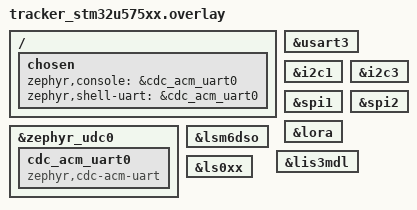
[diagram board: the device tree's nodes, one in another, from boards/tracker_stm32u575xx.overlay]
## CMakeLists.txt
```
cmake_minimum_required(VERSION 3.20.0)

list(APPEND ZEPHYR_EXTRA_MODULES
  ${CMAKE_CURRENT_SOURCE_DIR}/../../lib/ahrs
)

find_package(Zephyr REQUIRED HINTS $ENV{ZEPHYR_BASE})
project(compass_sample)

target_sources(app PRIVATE src/main.c)
```

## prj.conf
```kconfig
# Console over RTT (STLink v2 / OpenOCD)
CONFIG_LOG=y
CONFIG_LOG_BACKEND_RTT=y
CONFIG_LOG_BACKEND_UART=n
CONFIG_USE_SEGGER_RTT=y
CONFIG_CONSOLE=y
CONFIG_RTT_CONSOLE=y
CONFIG_UART_CONSOLE=n

# Sensors
CONFIG_SENSOR=y
CONFIG_I2C=y
CONFIG_LSM6DSO=y
CONFIG_LSM6DSO_TRIGGER_NONE=y
CONFIG_LIS3MDL=y
CONFIG_LIS3MDL_TRIGGER_NONE=y
CONFIG_LIS3MDL_ODR="20"

# AHRS library
CONFIG_AHRS=y
CONFIG_AHRS_ALPHA_X1000=960
CONFIG_AHRS_DT_MS=50

# Float printing
CONFIG_CBPRINTF_FP_SUPPORT=y

# FPU (Cortex-M33)
CONFIG_FPU=y

# Power domains (3V3 rail for sensors)
CONFIG_PM_DEVICE=y
CONFIG_PM_DEVICE_RUNTIME=y
CONFIG_PM_DEVICE_POWER_DOMAIN=y
CONFIG_TIMEOUT_64BIT=y
CONFIG_POWER_DOMAIN=y
CONFIG_POWER_DOMAIN_GPIO_INIT_PRIORITY=1

# Stack
CONFIG_MAIN_STACK_SIZE=4096
```

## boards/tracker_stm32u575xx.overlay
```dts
/*
 * Route console/log output to USB CDC ACM on the Tracker board.
 *
 * Power domains are removed from peripheral nodes to avoid init-ordering
 * conflicts. main.c drives the power GPIOs directly.
 */

&zephyr_udc0 {
	cdc_acm_uart0: cdc_acm_uart0 {
		compatible = "zephyr,cdc-acm-uart";
	};
};

/ {
	chosen {
		zephyr,console = &cdc_acm_uart0;
		zephyr,shell-uart = &cdc_acm_uart0;
	};
};

&usart3 { /delete-property/ power-domains; };
&i2c1   { /delete-property/ power-domains; };
&i2c3   { /delete-property/ power-domains; };
&spi1   { /delete-property/ power-domains; };
&spi2   { /delete-property/ power-domains; };
&lora   { /delete-property/ power-domains; };
&lsm6dso { /delete-property/ power-domains; };
&lis3mdl { /delete-property/ power-domains; };
&ls0xx  { /delete-property/ power-domains; };
```

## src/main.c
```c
/*
 * Tilt-compensated compass — uses the ahrs library
 *
 * Set calibration values below to match your board.
 * Output (20 Hz): "AHR:<roll>,<pitch>,<heading>  degrees"
 *
 * SPDX-License-Identifier: Apache-2.0
 */

#include <zephyr/kernel.h>
#include <zephyr/device.h>
#include <zephyr/pm/device_runtime.h>
#include <ahrs.h>

/* ── Calibration — paste values from your calibration samples ────────────── */

/* Gyro zero-rate bias in milli-degrees per second (from acc_calibration) */
#define GYRO_BIAS_X_MDPS   288.0f
#define GYRO_BIAS_Y_MDPS  -215.0f
#define GYRO_BIAS_Z_MDPS  -599.0f

/* Mag hard-iron offset in µT (from mag_calibration) */
static const float hard_iron[3] = { -49.20f, 49.96f, -27.15f };

/* Mag soft-iron correction matrix (from mag_calibration) */
static const float soft_iron[3][3] = {
	{ +0.979f, +0.044f, -0.015f },
	{ +0.044f, +1.005f, -0.004f },
	{ -0.015f, -0.004f, +1.019f },
};

/* ─────────────────────────────────────────────────────────────────────────── */

int main(void)
{
	pm_device_runtime_get(DEVICE_DT_GET(DT_NODELABEL(power_3v3)));

	const struct device *imu = DEVICE_DT_GET(DT_NODELABEL(lsm6dso));
	const struct device *mag = DEVICE_DT_GET(DT_NODELABEL(lis3mdl));

	if (ahrs_init(imu, mag) < 0) {
		printk("Sensor init failed\n");
		return -ENODEV;
	}

	ahrs_set_gyro_bias(GYRO_BIAS_X_MDPS, GYRO_BIAS_Y_MDPS, GYRO_BIAS_Z_MDPS);
	ahrs_set_mag_calibration(hard_iron, soft_iron);

	printk("Tilt-compensated compass starting...\n");

	while (1) {
		if (ahrs_update() == 0) {
			float roll, pitch, heading;

			ahrs_get(&roll, &pitch, &heading);
			printk("AHR:%8.2f,%8.2f,%8.2f\n",
			       (double)roll, (double)pitch, (double)heading);
		}

		k_msleep(CONFIG_AHRS_DT_MS);
	}

	return 0;
}
```
